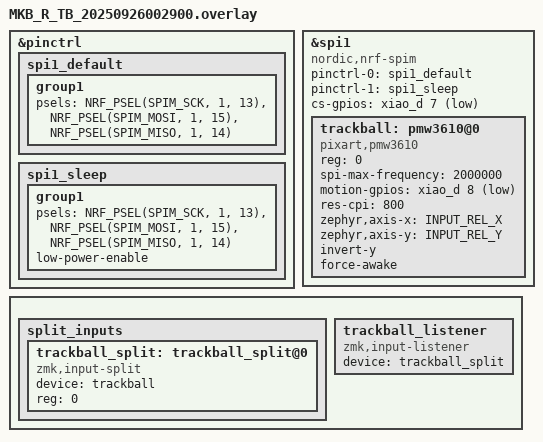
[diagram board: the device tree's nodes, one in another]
#include "MKB_R_Base.dtsi"

/* ---- XIAO nRF52840 既定SPIピン: SCK/D8=P1.13, MISO/D9=P1.14, MOSI/D10=P1.15 ---- */
&pinctrl {
    spi1_default: spi1_default {
        group1 {
            psels = <NRF_PSEL(SPIM_SCK,  1, 13)>,  /* D8  */
                    <NRF_PSEL(SPIM_MOSI, 1, 15)>,  /* D10 */
                    <NRF_PSEL(SPIM_MISO, 1, 14)>;  /* D9  */
        };
    };
    spi1_sleep: spi1_sleep {
        group1 {
            psels = <NRF_PSEL(SPIM_SCK,  1, 13)>,
                    <NRF_PSEL(SPIM_MOSI, 1, 15)>,
                    <NRF_PSEL(SPIM_MISO, 1, 14)>;
            low-power-enable;
        };
    };
};

/* ---- SPIコントローラは spi1 を使用（spi0でも良いがピン群と合わせる） ---- */
&spi1 {
    status = "okay";
    compatible = "nordic,nrf-spim";
    pinctrl-0 = <&spi1_default>;
    pinctrl-1 = <&spi1_sleep>;
    pinctrl-names = "default", "sleep";

    /* CS は D7 を採用（あなたの元設定と同じ）。reg=<0> と配列の先頭を対応させる */
    cs-gpios = <&xiao_d 7 GPIO_ACTIVE_LOW>;

    /* ---- PMW3610ノード（Zephyr公式bindingに準拠） ---- */
    trackball: pmw3610@0 {
        status = "okay";
        compatible = "pixart,pmw3610";
        reg = <0>;                       /* cs-gpios 配列のインデックス0 と一致 */
        spi-max-frequency = <2000000>;   /* まずは2MHz程度から */

        /* モーション割り込み。binding名は irq-gpios ではなく motion-gpios（Active Low） */
        motion-gpios = <&xiao_d 8 GPIO_ACTIVE_LOW>;  /* D8 をIRQに使う場合の例 */

        /* 解像度は res-cpi で指定 */
        res-cpi = <800>;

        /* 軸コードは zephyr,axis-x / zephyr,axis-y を使う */
        zephyr,axis-x = <INPUT_REL_X>;
        zephyr,axis-y = <INPUT_REL_Y>;

        /* 必要に応じて反転やスマートモード */
        // invert-x;
        invert-y;
        // smart-mode;
        force-awake;
    };
};

/* ---- input-split / listener（central側で有効化が原則） ---- */
{
    split_inputs {
        #address-cells = <1>;
        #size-cells = <0>;

        trackball_split: trackball_split@0 {
            compatible = "zmk,input-split";
            status = "okay";
            device = <&trackball>;
            reg = <0>;
        };
    };

    trackball_listener: trackball_listener {
        compatible = "zmk,input-listener";
        status = "okay";
        device = <&trackball_split>;
    };
};
